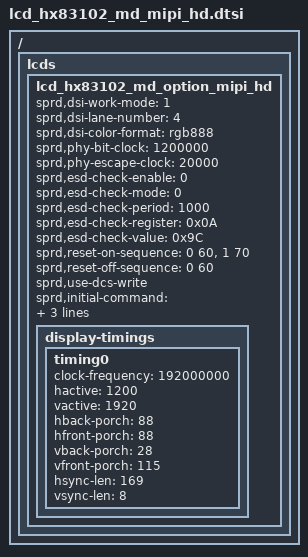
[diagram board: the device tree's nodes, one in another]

/*
 * tv105wum LCD config dtsi file for spreadtrum
 *
 * Copyright (C) 2018, Spreadtrum Communications Inc.
 * Copyright (C) 2023 Anhui Yunshu Zhihui Technology Co., Ltd.
 *
 * SPDX-License-Identifier: (GPL-2.0+ OR MIT)
 */

/ { lcds {
	lcd_hx83102_md_option_mipi_hd: lcd_hx83102_md_option_mipi_hd {

		sprd,dsi-work-mode = <1>; /* video burst mode*/
		sprd,dsi-lane-number = <4>;
		sprd,dsi-color-format = "rgb888";

		sprd,phy-bit-clock = <1200000>;	/* kbps */
		sprd,phy-escape-clock = <20000>;/* kHz */

		/*
		sprd,width-mm = <68>;
		sprd,height-mm = <121>;
		*/

		sprd,esd-check-enable = <0>;
		sprd,esd-check-mode = <0>;
		sprd,esd-check-period = <1000>;
		sprd,esd-check-register = <0x0A>;
		sprd,esd-check-value = <0x9C>;

		sprd,reset-on-sequence = <0 60>, <1 70>;
		sprd,reset-off-sequence = <0 60>;

		sprd,use-dcs-write;
		sprd,initial-command = [
			39 00 00 06 B9 83 10 21 55 00
			15 00 00 02 E9 C4
			15 00 00 02 D4 D3
			15 00 00 02 E9 3F
			39 00 00 1B B1 2C B5 B5 31 F1 33 C3 57 36 36 36 36 1A 8B 11 65 00 88 FA FF FF 8F FF 08 3C 33
			39 00 00 10 B2 00 47 B0 80 00 22 70 3C A1 22 00 00 00 88 F4
			39 00 00 0D B4 14 16 14 50 14 50 0D 6A 0D 6A 01 9E
			39 00 00 04 B6 34 34 03
			15 00 00 02 B8 40
			15 00 00 02 E9 CD
			15 00 00 02 BA 84
			15 00 00 02 E9 3F
			39 00 00 03 BC 1B 04
			15 00 00 02 BE 20
			39 00 00 03 BF FC C4
			39 00 00 0B C0 38 38 22 11 33 A0 61 08 F5 03
			15 00 00 02 E9 CC
			15 00 00 02 C7 80
			15 00 00 02 E9 3F
			15 00 00 02 E9 C6
			15 00 00 02 C8 97
			15 00 00 02 E9 3F
			39 00 00 06 C9 00 1E 30 D4 01
			39 00 00 07 CB 08 13 07 00 0F 16
			39 00 00 04 CC 02 03 44
			15 00 00 02 E9 C4
			15 00 00 02 D0 03
			15 00 00 02 E9 3F
			39 00 00 08 D1 37 06 00 02 04 2C FF
			39 00 00 23 D3 06 00 00 00 00 00 00 00 00 3B 03 73 3B 21 21 03 03 98 10 1D 00 1D 32 17 A1 07 A1 43 17 A6 07 A6 00 00
			39 00 00 2D D5 18 18 18 18 18 18 40 40 18 18 18 18 2A 2B 1F 1F 1E 1E 24 25 26 27 28 29 2A 2B 00 01 02 03 04 05 06 07 08 09 0A 0B 20 21 18 18 18 18
			39 00 00 2F E0 01 03 09 0F 16 24 3F 48 4F 4B 69 71 79 8C 8C 98 A1 B3 B3 58 5F 70 7F 00 01 09 0F 16 24 3F 48 4F 4B 69 71 79 8C 8C 98 A1 B3 B3 58 5F 64 67
			39 00 00 25 D8 02 AA EA AA AA 00 02 AA EA AA AA 00 00 00 00 00 00 00 00 00 00 00 00 00 00 00 00 00 00 00 00 00 00 00 00 00
			39 00 00 1A E7 07 10 10 2A 32 9F 01 5A 91 14 14 00 00 00 00 12 05 02 02 10 33 02 04 18 01
			15 00 00 02 BD 01
			39 00 00 05 B1 01 7F 11 FD
			15 00 00 02 CB 86
			15 00 00 02 D2 3D
			15 00 00 02 E9 C5
			39 00 00 08 D3 00 00 00 80 80 0C A1
			15 00 00 02 E9 3F
			39 00 00 25 D8 03 FF FF FF FF 00 03 FF FF FF FF 00 00 00 00 00 00 00 00 00 00 00 00 00 00 00 00 00 00 00 00 00 00 00 00 00
			39 00 00 10 E7 02 00 2D 01 7F 0F 7C 10 A0 00 00 77 00 00 00
			15 00 00 02 BD 02
			15 00 00 02 BF F2
			39 00 00 06 CB 02 00 00 10 58
			39 00 00 0D D2 0A 0A 05 03 0A 0A 01 03 01 01 05 0E
			15 00 00 02 E9 CC
			39 00 00 06 D3 03 1F E0 11 70
			15 00 00 02 E9 3F
			39 00 00 0D D8 AB FF FF FF FF A0 AB FF FF FF FF A0
			39 00 00 1D E7 FE 01 FE 01 FE 01 00 00 00 03 00 03 81 02 40 00 20 9E 02 01 00 00 00 00 00 00 00 00
			15 00 00 02 BD 03
			15 00 00 02 E9 C6
			39 00 00 04 B4 03 FF F8
			15 00 00 02 E9 3F
			39 00 00 25 D8 AA AB EA AA AA A0 AA AB EA AA AA A0 AA BF FF FF FE A0 AA BF FF FF FE A0 AA AA AA AA AA A0 AA AA AA AA AA A0
			15 00 00 02 E1 00
			15 00 00 02 BD 00
			15 00 00 02 E9 C4
			15 00 00 02 BA 96
			15 00 00 02 E9 3F
			15 00 00 02 BD 01
			15 00 00 02 E9 C5
			15 00 00 02 BA 4F
			15 00 00 02 E9 3F
			15 00 00 02 BD 02
			15 00 00 02 E9 CC
			15 00 00 02 BA 84
			15 00 00 02 E9 3F
			15 00 00 02 BD 00
			05 78 00 01 11
			05 14 00 01 29
			];

		sprd,sleep-in-command = [
			05 0A 00 01 28
			05 65 00 01 10
			];

/*		sprd,sleep-out-command = [
			13 64 00 01 11
			13 32 00 01 29
			]; */

		display-timings {
			timing0 {
				clock-frequency = <192000000>;
				hactive = <1200>;
				vactive = <1920>;
				hback-porch = <88>;
				hfront-porch = <88>;
				vback-porch = <28>;
				vfront-porch = <115>;
				hsync-len = <169>;
				vsync-len = <8>;
			};
		};
	};
};};
